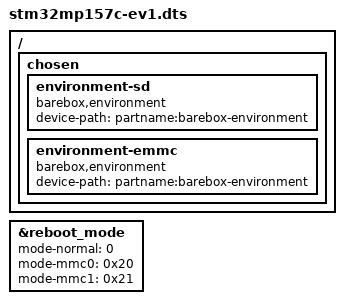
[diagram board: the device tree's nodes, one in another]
// SPDX-License-Identifier: (GPL-2.0+ OR X11)

#include <arm/stm32mp157c-ev1.dts>
#include "stm32mp151.dtsi"

/ {
	chosen {
		environment-sd {
			compatible = "barebox,environment";
			device-path = &sdmmc1, "partname:barebox-environment";
		};

		environment-emmc {
			compatible = "barebox,environment";
			device-path = &sdmmc2, "partname:barebox-environment";
		};
	};
};

&reboot_mode {
	mode-normal = <0>;
	mode-mmc0 = <0x20>;
	mode-mmc1 = <0x21>;
};
